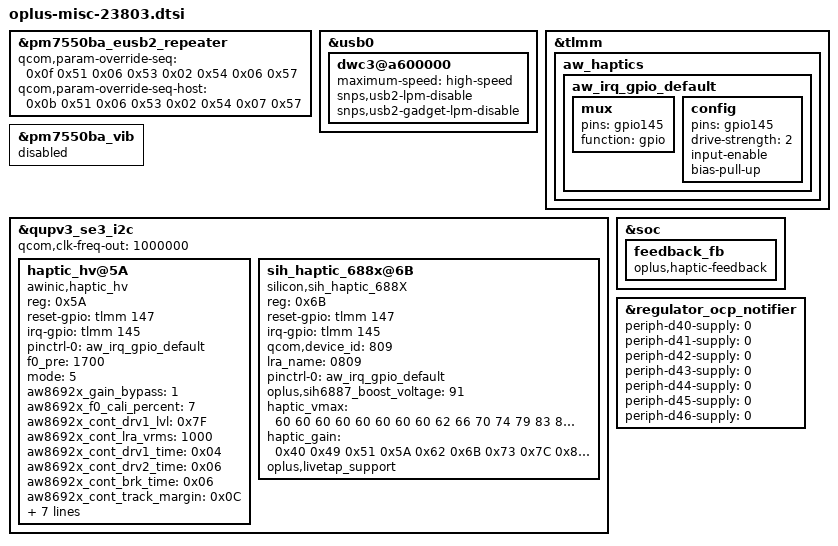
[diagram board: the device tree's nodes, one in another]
&pm7550ba_eusb2_repeater {
	qcom,param-override-seq = <0x0f 0x51 0x06 0x53 0x02 0x54 0x06 0x57>;
	qcom,param-override-seq-host = <0x0b 0x51 0x06 0x53 0x02 0x54 0x07 0x57>;
};

&usb0 {
	dwc3@a600000 {
		maximum-speed = "high-speed";
		snps,usb2-lpm-disable;
		snps,usb2-gadget-lpm-disable;
	};
};

&tlmm {
	aw_haptics: aw_haptics {
		aw_irq_gpio_default: aw_irq_gpio_default {
			mux {
				pins = "gpio145";
				function = "gpio";
			};

			config {
				pins = "gpio145";
				drive-strength = <2>;
				input-enable;
				bias-pull-up;
			};
		};
	};
};

&pm7550ba_vib {
	status = "disabled";
};

&qupv3_se3_i2c {
	qcom,clk-freq-out = <1000000>;
	status = "ok";
	/* AWINIC AW86927 Haptic, motor values as stock (device id 809) */
	haptic_hv@5A {
		compatible = "awinic,haptic_hv";
		reg = <0x5A>;
		reset-gpio = <&tlmm 147 0>;
		irq-gpio = <&tlmm 145 0>;
		status = "ok";
		pinctrl-names = "default";
		pinctrl-0 = <&aw_irq_gpio_default>;
		f0_pre = <1700>;
		mode = /bits/ 8 <5>;

		aw8692x_gain_bypass = /bits/ 8 <1>;
		aw8692x_f0_cali_percent = /bits/ 8 <7>;
		aw8692x_cont_drv1_lvl = /bits/ 8 <0x7F>;
		aw8692x_cont_lra_vrms = <1000>;
		aw8692x_cont_drv1_time = /bits/ 8 <0x04>;
		aw8692x_cont_drv2_time = /bits/ 8 <0x06>;
		aw8692x_cont_brk_time = /bits/ 8 <0x06>;
		aw8692x_cont_track_margin = /bits/ 8 <0x0C>;
		aw8692x_cont_brk_gain = /bits/ 8 <0x08>;
		aw8692x_d2s_gain = /bits/ 8 <0x06>;
		aw8692x_duration_time = /bits/ 8 <20 30 60>;
		aw8692x_trig_config = /bits/ 8 <0 0 0 1 0 2 0 0
						0 0 0 1 0 2 0 0
						0 0 0 1 0 2 0 0>;
		/* Boost register 0x50 */
		aw8692x_bst_vol_default = <8500>;
		aw8692x_is_enabled_track_en;
	};
	/* AWINIC AW86927 Haptic End */
// SIH6887 Haptic
	sih_haptic_688x@6B {
		compatible = "silicon,sih_haptic_688X";
		reg = <0x6B>;
		reset-gpio = <&tlmm 147 0x0>;
		irq-gpio = <&tlmm 145 0x0>;
		qcom,device_id = <809>;
		lra_name = "0809";
		pinctrl-names = "default";
		pinctrl-0 = <&aw_irq_gpio_default>;
		oplus,sih6887_boost_voltage = <91>; /* 9.1v */
		haptic_vmax = /bits/ 8 < 60 60 60 60 60 60 60 60 62 66 70 74 79 83 86 90 91 >;
		haptic_gain = /bits/ 8 < 0x40 0x49 0x51 0x5A 0x62 0x6B 0x73 0x7C 0x80 0x80 0x80 0x80 0x80 0x80 0x80 0x80 0x80 >;
		oplus,livetap_support;
		status = "okay";
	};
};

&soc {
	feedback_fb: feedback_fb {
		compatible = "oplus,haptic-feedback";
	};
};

&regulator_ocp_notifier {
	periph-d40-supply = <0>;
	periph-d41-supply = <0>;
	periph-d42-supply = <0>;
	periph-d43-supply = <0>;
	periph-d44-supply = <0>;
	periph-d45-supply = <0>;
	periph-d46-supply = <0>;
};
